# CORE_PRM register map
Vendor: Texas Instruments
Peripheral module from a debugger description file (folder TDA2Px).
Registers are 32-bit, access per field, reset 0x2 unless marked. A register's access mark holds for its fields unless they carry their own. Offsets are as the file gives them; lines under a group give offsets from that group; [hi:lo] are bit positions; {n}, {i} and the like mark numbered series; 'fields as' and 'values as' point back to an identical list; <NAME> marks a mode.

## CORE_PRM
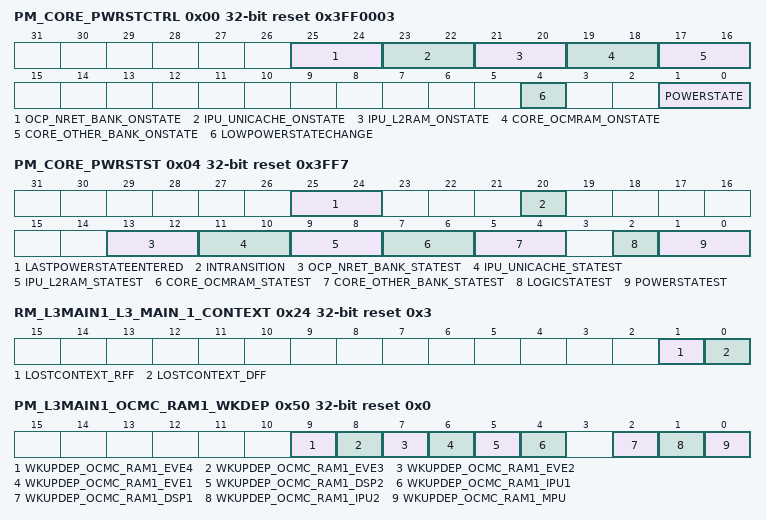
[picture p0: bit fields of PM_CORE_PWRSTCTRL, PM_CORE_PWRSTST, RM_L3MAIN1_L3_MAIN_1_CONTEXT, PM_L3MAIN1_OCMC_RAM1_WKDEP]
0x00 PM_CORE_PWRSTCTRL reset 0x3FF0003 — This register controls the CORE power state to reach upon a domain sleep transition
  [25:24] OCP_NRET_BANK_ONSTATE ro — OCP_WP bank and DMM bank2 state when domain is ON.
    3=MEM_ON (Memory bank is on when the domain is ON.)
  [23:22] IPU_UNICACHE_ONSTATE ro — IPU UNICACHE bank state when domain is ON.
    3=MEM_ON (Memory bank is on when the domain is ON.)
  [21:20] IPU_L2RAM_ONSTATE ro — IPU L2 bank state when domain is ON.
    3=MEM_ON (Memory bank is on when the domain is ON.)
  [19:18] CORE_OCMRAM_ONSTATE ro — OCMRAM bank state when domain is ON.
    3=MEM_ON (Memory bank is on when the domain is ON.)
  [17:16] CORE_OTHER_BANK_ONSTATE ro — DMA/ICR bank and DMM bank1 state when domain is ON.
    3=MEM_ON (Memory bank is on when the domain is ON.)
  [4] LOWPOWERSTATECHANGE rw — Power state change request when domain has already performed a sleep transition. Allows going into deeper low power state without waking up the power domain.
    0=DIS (Do not request a low power state change.); 1=EN (Request a low power state change. This bit is automatically cleared when the power state is effectively changed or when power state is ON.)
  [1:0] POWERSTATE rw — Power state control
    1=RET (Reserved); 2=INACT (Reserved); 3=ON (ON State)
0x04 PM_CORE_PWRSTST reset 0x3FF7 — This register provides a status on the current CORE power domain state. [warm reset insensitive]
  [25:24] LASTPOWERSTATEENTERED rw — Last low power state entered. Set to 0x3 upon write of the same only. This register is intended for debug purpose only.
    0=OFF (Power domain was previously OFF); 1=RET (Reserved); 2=INACTIVE (Reserved); 3=ON (Power domain was previously ON-ACTIVE)
  [20] INTRANSITION ro — Domain transition status
    0=NO (No on-going transition on power domain); 1=ONGOING (Power domain transition is in progress.)
  [13:12] OCP_NRET_BANK_STATEST ro — OCP_WP bank and DMM bank2 state status
    0=MEM_OFF (Memory is OFF); 3=MEM_ON (Memory is ON)
  [11:10] IPU_UNICACHE_STATEST ro — IPU UNICACHE bank state status
    0=MEM_OFF (Memory is OFF); 1=MEM_RET (Reserved); 3=MEM_ON (Memory is ON)
  [9:8] IPU_L2RAM_STATEST ro — IPU L2 bank state status
    values as IPU_UNICACHE_STATEST
  [7:6] CORE_OCMRAM_STATEST ro — OCMRAM bank state status
    values as IPU_UNICACHE_STATEST
  [5:4] CORE_OTHER_BANK_STATEST ro — DMA/ICR bank and DMM bank1 state status
    values as IPU_UNICACHE_STATEST
  [2] LOGICSTATEST ro — Logic state status
    0=OFF (Reserved); 1=ON (Logic in domain is ON)
  [1:0] POWERSTATEST ro — Current power state status
    1=RET (Reserved); 2=INACTIVE (Reserved); 3=ON (Power domain is ON-ACTIVE)
0x24 RM_L3MAIN1_L3_MAIN_1_CONTEXT reset 0x3 — This register contains dedicated L3_MAIN_1 context statuses. [warm reset insensitive]
  [1] LOSTCONTEXT_RFF rw — Specify if RFF-based context has been lost due to a previous power transition or other reset source. (set upon assertion of CORE_PWRON_RET_RST signal)
    0=MAINTAINED (Context has been maintained); 1=LOST (Context has been lost)
  [0] LOSTCONTEXT_DFF rw — Specify if DFF-based context has been lost due to a previous power transition or other reset source. (set upon assertion of CORE_RST signal)
    values as LOSTCONTEXT_RFF
0x2C RM_L3MAIN1_GPMC_CONTEXT — This register contains dedicated GPMC context statuses. [warm reset insensitive]
  [1] LOSTCONTEXT_RFF rw — Specify if RFF-based context has been lost due to a previous power transition or other reset source. (set upon assertion of CORE_RET_RST signal)
    values as RM_L3MAIN1_L3_MAIN_1_CONTEXT.LOSTCONTEXT_RFF
0x34 RM_L3MAIN1_MMU_EDMA_CONTEXT — This register contains dedicated MMU context statuses. [warm reset insensitive]
  [1] LOSTCONTEXT_RFF rw — Specify if RFF-based context has been lost due to a previous power transition or other reset source. (set upon assertion of CORE_PWRON_RET_RST signal)
    values as RM_L3MAIN1_L3_MAIN_1_CONTEXT.LOSTCONTEXT_RFF
0x4C RM_L3MAIN1_MMU_PCIESS_CONTEXT — This register contains dedicated MMU context statuses. [warm reset insensitive]
  fields as RM_L3MAIN1_MMU_EDMA_CONTEXT
0x50 PM_L3MAIN1_OCMC_RAM1_WKDEP reset 0x0 — This register controls wakeup dependency based on OCMC_RAM1 service requests.
  [9] WKUPDEP_OCMC_RAM1_EVE4 rw — Wakeup dependency from OCMC_RAM1 module (SWakeup signal) towards EVE4 + L3_MAIN1 + L4PER1 + L4PER2 + L4PER3 domainsEVE4 is not supported in this family of devices.
    0=DISABLED (Dependency is disabled); 1=ENABLED (Dependency is enabled)
  [8] WKUPDEP_OCMC_RAM1_EVE3 rw — Wakeup dependency from OCMC_RAM1 module (SWakeup signal) towards EVE3 + L3_MAIN1 + L4PER1 + L4PER2 + L4PER3 domainsEVE3 is not supported in this family of devices.
    values as WKUPDEP_OCMC_RAM1_EVE4
  [7] WKUPDEP_OCMC_RAM1_EVE2 rw — Wakeup dependency from OCMC_RAM1 module (SWakeup signal) towards EVE2 + L3_MAIN1 + L4PER1 + L4PER2 + L4PER3 domains
    values as WKUPDEP_OCMC_RAM1_EVE4
  [6] WKUPDEP_OCMC_RAM1_EVE1 rw — Wakeup dependency from OCMC_RAM1 module (SWakeup signal) towards EVE1 + L3_MAIN1 + L4PER1 + L4PER2 + L4PER3 domains
    values as WKUPDEP_OCMC_RAM1_EVE4
  [5] WKUPDEP_OCMC_RAM1_DSP2 rw — Wakeup dependency from OCMC_RAM1 module (SWakeup signal) towards DSP2 + L3_MAIN1 + L4PER1 + L4PER2 + L4PER3 domains
    values as WKUPDEP_OCMC_RAM1_EVE4
  [4] WKUPDEP_OCMC_RAM1_IPU1 rw — Wakeup dependency from OCMC_RAM1 module (SWakeup signal) towards IPU1 + L3_MAIN1 + L4PER1 + L4PER2 + L4PER3 domains
    values as WKUPDEP_OCMC_RAM1_EVE4
  [2] WKUPDEP_OCMC_RAM1_DSP1 rw — Wakeup dependency from OCMC_RAM1 module (SWakeup signal) towards DSP + L3_MAIN1 + L4PER1 + L4PER2 + L4PER3 domains
    values as WKUPDEP_OCMC_RAM1_EVE4
  [1] WKUPDEP_OCMC_RAM1_IPU2 rw — Wakeup dependency from OCMC_RAM1 module (SWakeup signal) towards IPU2 + L3_MAIN1 + L4PER1 + L4PER2 + L4PER3 domains
    0=Dependency_is_disabled; 1=Dependency_is_enabled
  [0] WKUPDEP_OCMC_RAM1_MPU rw — Wakeup dependency from OCMC_RAM1 module (SWakeup signal) towards MPU + L3_MAIN1 + L4PER1 + L4PER2 + L4PER3 domains
    values as WKUPDEP_OCMC_RAM1_EVE4
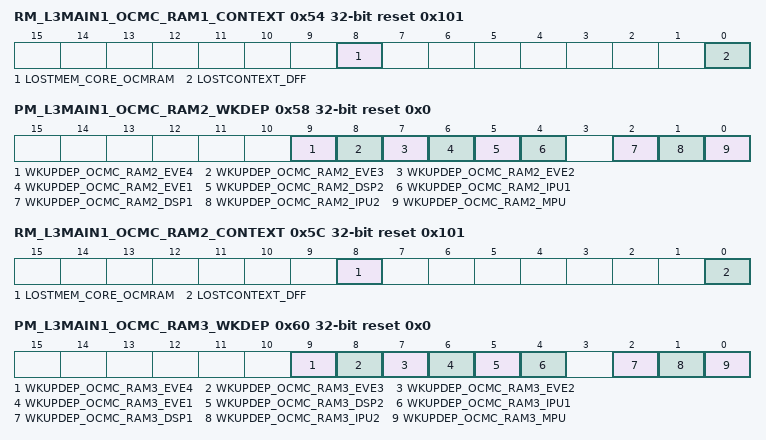
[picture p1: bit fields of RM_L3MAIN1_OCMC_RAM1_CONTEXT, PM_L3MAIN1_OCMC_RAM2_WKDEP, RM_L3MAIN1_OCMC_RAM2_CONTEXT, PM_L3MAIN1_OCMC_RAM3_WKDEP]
0x54 RM_L3MAIN1_OCMC_RAM1_CONTEXT reset 0x101 — This register contains dedicated OCMC_RAM context statuses. [warm reset insensitive]
  [8] LOSTMEM_CORE_OCMRAM rw — Specify if memory-based context in CORE_OCMRAM memory bank has been lost due to a previous power transition or other reset source (not affected by a global warm reset).
    values as RM_L3MAIN1_L3_MAIN_1_CONTEXT.LOSTCONTEXT_RFF
  [0] LOSTCONTEXT_DFF rw — Specify if DFF-based context has been lost due to a previous power transition or other reset source. (set upon assertion of CORE_RST signal)
    values as RM_L3MAIN1_L3_MAIN_1_CONTEXT.LOSTCONTEXT_RFF
0x58 PM_L3MAIN1_OCMC_RAM2_WKDEP reset 0x0 — This register controls wakeup dependency based on OCMC_RAM2 service requests.
  [9] WKUPDEP_OCMC_RAM2_EVE4 rw — Wakeup dependency from OCMC_RAM2 module (SWakeup signal) towards EVE4 + L3_MAIN1 + L4PER1 + L4PER2 + L4PER3 domainsEVE4 is not supported in this family of devices.
    values as PM_L3MAIN1_OCMC_RAM1_WKDEP.WKUPDEP_OCMC_RAM1_EVE4
  [8] WKUPDEP_OCMC_RAM2_EVE3 rw — Wakeup dependency from OCMC_RAM2 module (SWakeup signal) towards EVE3 + L3_MAIN1 + L4PER1 + L4PER2 + L4PER3 domainsEVE3 is not supported in this family of devices.
    values as PM_L3MAIN1_OCMC_RAM1_WKDEP.WKUPDEP_OCMC_RAM1_EVE4
  [7] WKUPDEP_OCMC_RAM2_EVE2 rw — Wakeup dependency from OCMC_RAM2 module (SWakeup signal) towards EVE2 + L3_MAIN1 + L4PER1 + L4PER2 + L4PER3 domains
    values as PM_L3MAIN1_OCMC_RAM1_WKDEP.WKUPDEP_OCMC_RAM1_EVE4
  [6] WKUPDEP_OCMC_RAM2_EVE1 rw — Wakeup dependency from OCMC_RAM2 module (SWakeup signal) towards EVE1 + L3_MAIN1 + L4PER1 + L4PER2 + L4PER3 domains
    values as PM_L3MAIN1_OCMC_RAM1_WKDEP.WKUPDEP_OCMC_RAM1_EVE4
  [5] WKUPDEP_OCMC_RAM2_DSP2 rw — Wakeup dependency from OCMC_RAM2 module (SWakeup signal) towards DSP2 + L3_MAIN1 + L4PER1 + L4PER2 + L4PER3 domains
    values as PM_L3MAIN1_OCMC_RAM1_WKDEP.WKUPDEP_OCMC_RAM1_EVE4
  [4] WKUPDEP_OCMC_RAM2_IPU1 rw — Wakeup dependency from OCMC_RAM2 module (SWakeup signal) towards IPU1 + L3_MAIN1 + L4PER1 + L4PER2 + L4PER3 domains
    values as PM_L3MAIN1_OCMC_RAM1_WKDEP.WKUPDEP_OCMC_RAM1_EVE4
  [2] WKUPDEP_OCMC_RAM2_DSP1 rw — Wakeup dependency from OCMC_RAM2 module (SWakeup signal) towards DSP + L3_MAIN1 + L4PER1 + L4PER2 + L4PER3 domains
    values as PM_L3MAIN1_OCMC_RAM1_WKDEP.WKUPDEP_OCMC_RAM1_EVE4
  [1] WKUPDEP_OCMC_RAM2_IPU2 rw — Wakeup dependency from OCMC_RAM2 module (SWakeup signal) towards IPU2 + L3_MAIN1 + L4PER1 + L4PER2 + L4PER3 domains
    0=Dependency_is_disabled; 1=Dependency_is_enabled
  [0] WKUPDEP_OCMC_RAM2_MPU rw — Wakeup dependency from OCMC_RAM2 module (SWakeup signal) towards MPU + L3_MAIN1 + L4PER1 + L4PER2 + L4PER3 domains
    values as PM_L3MAIN1_OCMC_RAM1_WKDEP.WKUPDEP_OCMC_RAM1_EVE4
0x5C RM_L3MAIN1_OCMC_RAM2_CONTEXT reset 0x101 — This register contains dedicated OCMC_RAM2 context statuses. [warm reset insensitive]
  fields as RM_L3MAIN1_OCMC_RAM1_CONTEXT
0x60 PM_L3MAIN1_OCMC_RAM3_WKDEP reset 0x0 — This register controls wakeup dependency based on OCMC_RAM3 service requests.
  [9] WKUPDEP_OCMC_RAM3_EVE4 rw — Wakeup dependency from OCMC_RAM3 module (SWakeup signal) towards EVE4 + L3_MAIN1 + L4PER1 + L4PER2 + L4PER3 domainsEVE4 is not supported in this family of devices.
    values as PM_L3MAIN1_OCMC_RAM1_WKDEP.WKUPDEP_OCMC_RAM1_EVE4
  [8] WKUPDEP_OCMC_RAM3_EVE3 rw — Wakeup dependency from OCMC_RAM3 module (SWakeup signal) towards EVE3 + L3_MAIN1 + L4PER1 + L4PER2 + L4PER3 domainsEVE3 is not supported in this family of devices.
    values as PM_L3MAIN1_OCMC_RAM1_WKDEP.WKUPDEP_OCMC_RAM1_EVE4
  [7] WKUPDEP_OCMC_RAM3_EVE2 rw — Wakeup dependency from OCMC_RAM3 module (SWakeup signal) towards EVE2 + L3_MAIN1 + L4PER1 + L4PER2 + L4PER3 domains
    values as PM_L3MAIN1_OCMC_RAM1_WKDEP.WKUPDEP_OCMC_RAM1_EVE4
  [6] WKUPDEP_OCMC_RAM3_EVE1 rw — Wakeup dependency from OCMC_RAM3 module (SWakeup signal) towards EVE1 + L3_MAIN1 + L4PER1 + L4PER2 + L4PER3 domains
    values as PM_L3MAIN1_OCMC_RAM1_WKDEP.WKUPDEP_OCMC_RAM1_EVE4
  [5] WKUPDEP_OCMC_RAM3_DSP2 rw — Wakeup dependency from OCMC_RAM3 module (SWakeup signal) towards DSP2 + L3_MAIN1 + L4PER1 + L4PER2 + L4PER3 domains
    values as PM_L3MAIN1_OCMC_RAM1_WKDEP.WKUPDEP_OCMC_RAM1_EVE4
  [4] WKUPDEP_OCMC_RAM3_IPU1 rw — Wakeup dependency from OCMC_RAM3 module (SWakeup signal) towards IPU1 + L3_MAIN1 + L4PER1 + L4PER2 + L4PER3 domains
    values as PM_L3MAIN1_OCMC_RAM1_WKDEP.WKUPDEP_OCMC_RAM1_EVE4
  [2] WKUPDEP_OCMC_RAM3_DSP1 rw — Wakeup dependency from OCMC_RAM3 module (SWakeup signal) towards DSP + L3_MAIN1 + L4PER1 + L4PER2 + L4PER3 domains
    values as PM_L3MAIN1_OCMC_RAM1_WKDEP.WKUPDEP_OCMC_RAM1_EVE4
  [1] WKUPDEP_OCMC_RAM3_IPU2 rw — Wakeup dependency from OCMC_RAM3 module RW 0x0 (SWakeup signal) towards IPU2 + L3_MAIN1 + L4PER1 + L4PER2 + L4PER3 domains
    0=Dependency_is_disabled; 1=Dependency_is_enabled
  [0] WKUPDEP_OCMC_RAM3_MPU rw — Wakeup dependency from OCMC_RAM3 module (SWakeup signal) towards MPU + L3_MAIN1 + L4PER1 + L4PER2 + L4PER3 domains
    values as PM_L3MAIN1_OCMC_RAM1_WKDEP.WKUPDEP_OCMC_RAM1_EVE4
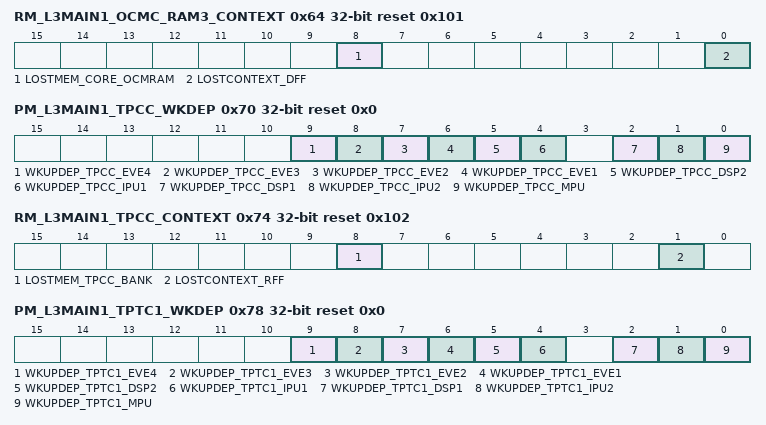
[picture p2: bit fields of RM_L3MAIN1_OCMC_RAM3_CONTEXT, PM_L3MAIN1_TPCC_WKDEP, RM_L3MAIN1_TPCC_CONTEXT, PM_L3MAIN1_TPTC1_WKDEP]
0x64 RM_L3MAIN1_OCMC_RAM3_CONTEXT reset 0x101 — This register contains dedicated OCMC_RAM3 context statuses. [warm reset insensitive]
  fields as RM_L3MAIN1_OCMC_RAM1_CONTEXT
0x70 PM_L3MAIN1_TPCC_WKDEP reset 0x0 — This register controls wakeup dependency based on TPCC service requests.
  [9] WKUPDEP_TPCC_EVE4 rw — Wakeup dependency from TPCC module (SWakeup signal) towards EVE4 + L3_MAIN1 + L4PER1 + L4PER2 + L4PER3 domainsEVE4 is not supported in this family of devices.
    values as PM_L3MAIN1_OCMC_RAM1_WKDEP.WKUPDEP_OCMC_RAM1_EVE4
  [8] WKUPDEP_TPCC_EVE3 rw — Wakeup dependency from TPCC module (SWakeup signal) towards EVE3 + L3_MAIN1 + L4PER1 + L4PER2 + L4PER3 domainsEVE3 is not supported in this family of devices.
    values as PM_L3MAIN1_OCMC_RAM1_WKDEP.WKUPDEP_OCMC_RAM1_EVE4
  [7] WKUPDEP_TPCC_EVE2 rw — Wakeup dependency from TPCC module (SWakeup signal) towards EVE2 + L3_MAIN1 + L4PER1 + L4PER2 + L4PER3 domains
    values as PM_L3MAIN1_OCMC_RAM1_WKDEP.WKUPDEP_OCMC_RAM1_EVE4
  [6] WKUPDEP_TPCC_EVE1 rw — Wakeup dependency from TPCC module (SWakeup signal) towards EVE1 + L3_MAIN1 + L4PER1 + L4PER2 + L4PER3 domains
    values as PM_L3MAIN1_OCMC_RAM1_WKDEP.WKUPDEP_OCMC_RAM1_EVE4
  [5] WKUPDEP_TPCC_DSP2 rw — Wakeup dependency from TPCC module (SWakeup signal) towards DSP2 + L3_MAIN1 + L4PER1 + L4PER2 + L4PER3 domains
    values as PM_L3MAIN1_OCMC_RAM1_WKDEP.WKUPDEP_OCMC_RAM1_EVE4
  [4] WKUPDEP_TPCC_IPU1 rw — Wakeup dependency from TPCC module (SWakeup signal) towards IPU1 + L3_MAIN1 + L4PER1 + L4PER2 + L4PER3 domains
    values as PM_L3MAIN1_OCMC_RAM1_WKDEP.WKUPDEP_OCMC_RAM1_EVE4
  [2] WKUPDEP_TPCC_DSP1 rw — Wakeup dependency from TPCC module (SWakeup signal) towards DSP + L3_MAIN1 + L4PER1 + L4PER2 + L4PER3 domains
    values as PM_L3MAIN1_OCMC_RAM1_WKDEP.WKUPDEP_OCMC_RAM1_EVE4
  [1] WKUPDEP_TPCC_IPU2 rw — Wakeup dependency from TPCC module (SWakeup signal) towards IPU2 + L3_MAIN1 + L4PER1 + L4PER2 + L4PER3 domains
    0=Dependency_is_disabled; 1=Dependency_is_enabled
  [0] WKUPDEP_TPCC_MPU rw — Wakeup dependency from TPCC module (SWakeup signal) towards MPU + L3_MAIN1 + L4PER1 + L4PER2 + L4PER3 domains
    values as PM_L3MAIN1_OCMC_RAM1_WKDEP.WKUPDEP_OCMC_RAM1_EVE4
0x74 RM_L3MAIN1_TPCC_CONTEXT reset 0x102 — This register contains dedicated TPCC context statuses. [warm reset insensitive]
  [8] LOSTMEM_TPCC_BANK rw — Specify if memory-based context in TPCC_MEM memory bank has been lost due to a previous power transition or other reset source (not affected by a global warm reset).
    values as RM_L3MAIN1_L3_MAIN_1_CONTEXT.LOSTCONTEXT_RFF
  [1] LOSTCONTEXT_RFF rw — Specify if RFF-based context has been lost due to a previous power transition or other reset source. (set upon assertion of CORE_RET_RST signal)
    values as RM_L3MAIN1_L3_MAIN_1_CONTEXT.LOSTCONTEXT_RFF
0x78 PM_L3MAIN1_TPTC1_WKDEP reset 0x0 — This register controls wakeup dependency based on TPTC service requests.
  [9] WKUPDEP_TPTC1_EVE4 rw — Wakeup dependency from TPTC module (SWakeup signal) towards EVE4 + L3_MAIN1 + L4PER1 + L4PER2 + L4PER3 domainsEVE4 is not supported in this family of devices.
    values as PM_L3MAIN1_OCMC_RAM1_WKDEP.WKUPDEP_OCMC_RAM1_EVE4
  [8] WKUPDEP_TPTC1_EVE3 rw — Wakeup dependency from TPTC module (SWakeup signal) towards EVE3 + L3_MAIN1 + L4PER1 + L4PER2 + L4PER3 domainsEVE3 is not supported in this family of devices.
    values as PM_L3MAIN1_OCMC_RAM1_WKDEP.WKUPDEP_OCMC_RAM1_EVE4
  [7] WKUPDEP_TPTC1_EVE2 rw — Wakeup dependency from TPTC module (SWakeup signal) towards EVE2 + L3_MAIN1 + L4PER1 + L4PER2 + L4PER3 domains
    values as PM_L3MAIN1_OCMC_RAM1_WKDEP.WKUPDEP_OCMC_RAM1_EVE4
  [6] WKUPDEP_TPTC1_EVE1 rw — Wakeup dependency from TPTC module (SWakeup signal) towards EVE1 + L3_MAIN1 + L4PER1 + L4PER2 + L4PER3 domains
    values as PM_L3MAIN1_OCMC_RAM1_WKDEP.WKUPDEP_OCMC_RAM1_EVE4
  [5] WKUPDEP_TPTC1_DSP2 rw — Wakeup dependency from TPTC module (SWakeup signal) towards DSP2 + L3_MAIN1 + L4PER1 + L4PER2 + L4PER3 domains
    values as PM_L3MAIN1_OCMC_RAM1_WKDEP.WKUPDEP_OCMC_RAM1_EVE4
  [4] WKUPDEP_TPTC1_IPU1 rw — Wakeup dependency from TPTC module (SWakeup signal) towards IPU1 + L3_MAIN1 + L4PER1 + L4PER2 + L4PER3 domains
    values as PM_L3MAIN1_OCMC_RAM1_WKDEP.WKUPDEP_OCMC_RAM1_EVE4
  [2] WKUPDEP_TPTC1_DSP1 rw — Wakeup dependency from TPTC module (SWakeup signal) towards DSP + L3_MAIN1 + L4PER1 + L4PER2 + L4PER3 domains
    values as PM_L3MAIN1_OCMC_RAM1_WKDEP.WKUPDEP_OCMC_RAM1_EVE4
  [1] WKUPDEP_TPTC1_IPU2 rw — Wakeup dependency from TPTC module (SWakeup signal) towards IPU2 + L3_MAIN1 + L4PER1 + L4PER2 + L4PER3 domains
    0=Dependency_is_disabled; 1=Dependency_is_enabled
  [0] WKUPDEP_TPTC1_MPU rw — Wakeup dependency from TPTC module (SWakeup signal) towards MPU + L3_MAIN1 + L4PER1 + L4PER2 + L4PER3 domains
    values as PM_L3MAIN1_OCMC_RAM1_WKDEP.WKUPDEP_OCMC_RAM1_EVE4
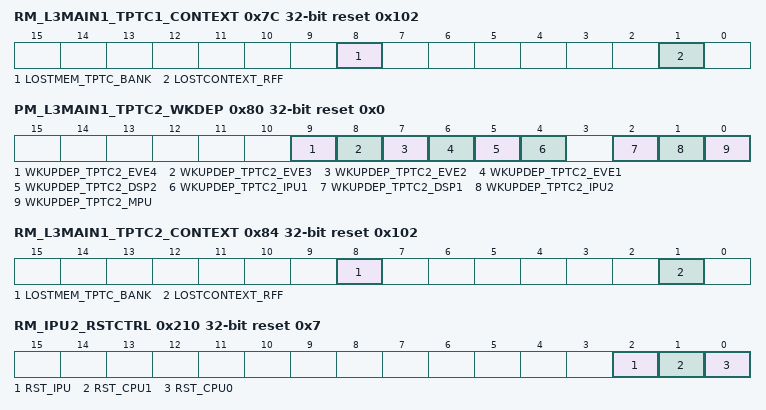
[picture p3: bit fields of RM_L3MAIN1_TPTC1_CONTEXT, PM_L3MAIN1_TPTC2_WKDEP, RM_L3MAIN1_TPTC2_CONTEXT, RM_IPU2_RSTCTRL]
0x7C RM_L3MAIN1_TPTC1_CONTEXT reset 0x102 — This register contains dedicated TPTC1 context statuses. [warm reset insensitive]
  [8] LOSTMEM_TPTC_BANK rw — Specify if memory-based context in TPTC_MEM memory bank has been lost due to a previous power transition or other reset source (not affected by a global warm reset).
    values as RM_L3MAIN1_L3_MAIN_1_CONTEXT.LOSTCONTEXT_RFF
  [1] LOSTCONTEXT_RFF rw — Specify if RFF-based context has been lost due to a previous power transition or other reset source. (set upon assertion of CORE_RET_RST signal)
    values as RM_L3MAIN1_L3_MAIN_1_CONTEXT.LOSTCONTEXT_RFF
0x80 PM_L3MAIN1_TPTC2_WKDEP reset 0x0 — This register controls wakeup dependency based on TPTC service requests.
  [9] WKUPDEP_TPTC2_EVE4 rw — Wakeup dependency from TPTC module (SWakeup signal) towards EVE4 + L3_MAIN1 + L4PER1 + L4PER2 + L4PER3 domainsEVE4 is not supported in this family of devices.
    values as PM_L3MAIN1_OCMC_RAM1_WKDEP.WKUPDEP_OCMC_RAM1_EVE4
  [8] WKUPDEP_TPTC2_EVE3 rw — Wakeup dependency from TPTC module (SWakeup signal) towards EVE3 + L3_MAIN1 + L4PER1 + L4PER2 + L4PER3 domainsEVE3 is not supported in this family of devices.
    values as PM_L3MAIN1_OCMC_RAM1_WKDEP.WKUPDEP_OCMC_RAM1_EVE4
  [7] WKUPDEP_TPTC2_EVE2 rw — Wakeup dependency from TPTC module (SWakeup signal) towards EVE2 + L3_MAIN1 + L4PER1 + L4PER2 + L4PER3 domains
    values as PM_L3MAIN1_OCMC_RAM1_WKDEP.WKUPDEP_OCMC_RAM1_EVE4
  [6] WKUPDEP_TPTC2_EVE1 rw — Wakeup dependency from TPTC module (SWakeup signal) towards EVE1 + L3_MAIN1 + L4PER1 + L4PER2 + L4PER3 domains
    values as PM_L3MAIN1_OCMC_RAM1_WKDEP.WKUPDEP_OCMC_RAM1_EVE4
  [5] WKUPDEP_TPTC2_DSP2 rw — Wakeup dependency from TPTC module (SWakeup signal) towards DSP2 + L3_MAIN1 + L4PER1 + L4PER2 + L4PER3 domains
    values as PM_L3MAIN1_OCMC_RAM1_WKDEP.WKUPDEP_OCMC_RAM1_EVE4
  [4] WKUPDEP_TPTC2_IPU1 rw — Wakeup dependency from TPTC module (SWakeup signal) towards IPU1 + L3_MAIN1 + L4PER1 + L4PER2 + L4PER3 domains
    values as PM_L3MAIN1_OCMC_RAM1_WKDEP.WKUPDEP_OCMC_RAM1_EVE4
  [2] WKUPDEP_TPTC2_DSP1 rw — Wakeup dependency from TPTC module (SWakeup signal) towards DSP + L3_MAIN1 + L4PER1 + L4PER2 + L4PER3 domains
    values as PM_L3MAIN1_OCMC_RAM1_WKDEP.WKUPDEP_OCMC_RAM1_EVE4
  [1] WKUPDEP_TPTC2_IPU2 rw — Wakeup dependency from TPTC module (SWakeup signal) towards IPU2 + L3_MAIN1 + L4PER1 + L4PER2 + L4PER3 domains
    0=Dependency_is_disabled; 1=Dependency_is_enabled
  [0] WKUPDEP_TPTC2_MPU rw — Wakeup dependency from TPTC module (SWakeup signal) towards MPU + L3_MAIN1 + L4PER1 + L4PER2 + L4PER3 domains
    values as PM_L3MAIN1_OCMC_RAM1_WKDEP.WKUPDEP_OCMC_RAM1_EVE4
0x84 RM_L3MAIN1_TPTC2_CONTEXT reset 0x102 — This register contains dedicated TPTC2 context statuses. [warm reset insensitive]
  fields as RM_L3MAIN1_TPTC1_CONTEXT
0x210 RM_IPU2_RSTCTRL reset 0x7 — This register controls the release of the IPU2 sub-system resets.
  [2] RST_IPU rw — IPU system reset control.
    0=CLEAR (Reset is cleared for IPU CACHE MMU); 1=ASSERT (Reset is asserted for the IPU CACHE MMU)
  [1] RST_CPU1 rw — IPU Cortex M4 CPU1 reset control
    0=CLEAR (Reset is cleared for the IPU Cortex M4 CPU1); 1=ASSERT (Reset is asserted for the IPU Cortex M4 CPU1)
  [0] RST_CPU0 rw — IPU Cortex M4 CPU0 reset control.
    0=CLEAR (Reset is cleared for the IPU Cortex M4 CPU0); 1=ASSERT (Reset is asserted for the IPU Cortex M4 CPU0)
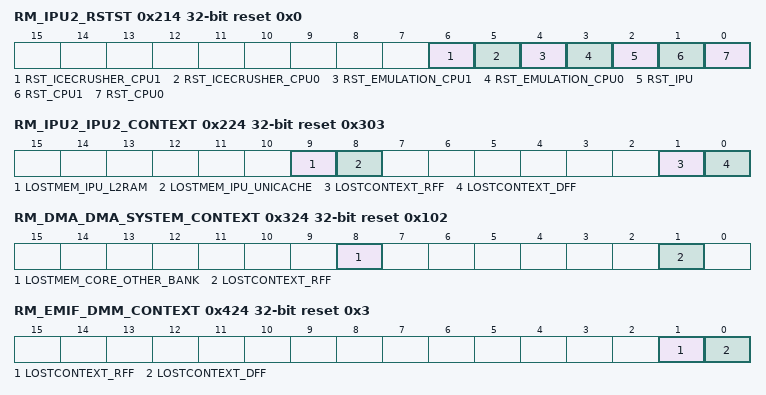
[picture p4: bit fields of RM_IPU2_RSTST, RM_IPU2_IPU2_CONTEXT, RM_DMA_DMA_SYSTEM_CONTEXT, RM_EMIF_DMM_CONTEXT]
0x214 RM_IPU2_RSTST reset 0x0 — This register logs the different reset sources of the IPU2 SS. Each bit is set upon release of the domain reset signal. Must be cleared by software. [warm reset insensitive]
  [6] RST_ICECRUSHER_CPU1 rw — Cortex M4 CPU1 has been reset due to IPU ICECRUSHER1 reset source
    0=RESET_NO (No icecrusher reset); 1=RESET_YES (CPU1 has been reset upon icecrusher reset)
  [5] RST_ICECRUSHER_CPU0 rw — Cortex M4 CPU0 has been reset due to IPU ICECRUSHER0 reset source
    0=RESET_NO (No icecrusher reset); 1=RESET_YES (CPU0 has been reset upon icecrusher reset)
  [4] RST_EMULATION_CPU1 rw — Cortex M4 CPU1 has been reset due to emulation reset source e.g. assert reset command initiated by the icepick module
    0=RESET_NO (No emulation reset); 1=RESET_YES (CPU1 has been reset upon emulation reset)
  [3] RST_EMULATION_CPU0 rw — Cortex M4 CPU0 has been reset due to emulation reset source e.g. assert reset command initiated by the icepick module
    0=RESET_NO (No emulation reset); 1=RESET_YES (CPU0 has been reset upon emulation reset)
  [2] RST_IPU rw — IPU system SW reset status
    0=RESET_NO (No SW reset occurred); 1=RESET_YES (IPU MMU and CACHE interface has been reset upon SW reset)
  [1] RST_CPU1 rw — IPU Cortex-M4 CPU1 SW reset status
    0=RESET_NO (No SW reset occurred); 1=RESET_YES (Cortex M4 CPU1 has been reset upon SW reset)
  [0] RST_CPU0 rw — IPU Cortex-M4 CPU0 SW reset status
    0=RESET_NO (No SW reset occurred); 1=RESET_YES (Cortex M4 CPU0 has been reset upon SW reset)
0x224 RM_IPU2_IPU2_CONTEXT reset 0x303 — This register contains dedicated IPU2 context statuses. [warm reset insensitive]
  [all] fields
    values as RM_L3MAIN1_L3_MAIN_1_CONTEXT.LOSTCONTEXT_RFF
  [9] LOSTMEM_IPU_L2RAM rw — Specify if memory-based context in IPU_L2RAM memory bank has been lost due to a previous power transition or other reset source.
  [8] LOSTMEM_IPU_UNICACHE rw — Specify if memory-based context in IPU_UNICACHE memory bank has been lost due to a previous power transition or other reset source.
  [1] LOSTCONTEXT_RFF rw — Specify if RFF-based context has been lost due to a previous power transition or other reset source. (set upon assertion of IPU_RET_RST signal)
  [0] LOSTCONTEXT_DFF rw — Specify if DFF-based context has been lost due to a previous power transition or other reset source. (set upon assertion of IPU_RST signal)
0x324 RM_DMA_DMA_SYSTEM_CONTEXT reset 0x102 — This register contains dedicated SDMA context statuses. [warm reset insensitive]
  [8] LOSTMEM_CORE_OTHER_BANK rw — Specify if memory-based context in CORE_OTHER_BANK memory bank has been lost due to a previous power transition or other reset source.
    values as RM_L3MAIN1_L3_MAIN_1_CONTEXT.LOSTCONTEXT_RFF
  [1] LOSTCONTEXT_RFF rw — Specify if RFF-based context has been lost due to a previous power transition or other reset source. (set upon assertion of DMA_RET_RST signal)
    values as RM_L3MAIN1_L3_MAIN_1_CONTEXT.LOSTCONTEXT_RFF
0x424 RM_EMIF_DMM_CONTEXT reset 0x3 — This register contains dedicated DMM context statuses. [warm reset insensitive]
  [1] LOSTCONTEXT_RFF rw — Specify if RFF-based context has been lost due to a previous power transition or other reset source. (set upon assertion of CORE_PWRON_RET_RST signal)
    values as RM_L3MAIN1_L3_MAIN_1_CONTEXT.LOSTCONTEXT_RFF
  [0] LOSTCONTEXT_DFF rw — Specify if DFF-based context has been lost due to a previous power transition or other reset source. (set upon assertion of CORE_PWRON_RST signal)
    values as RM_L3MAIN1_L3_MAIN_1_CONTEXT.LOSTCONTEXT_RFF
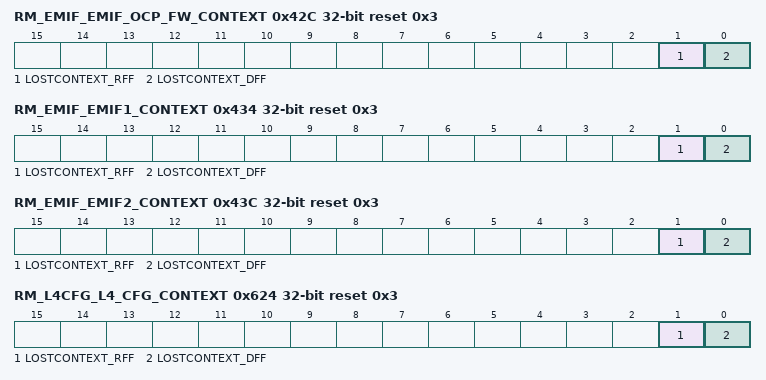
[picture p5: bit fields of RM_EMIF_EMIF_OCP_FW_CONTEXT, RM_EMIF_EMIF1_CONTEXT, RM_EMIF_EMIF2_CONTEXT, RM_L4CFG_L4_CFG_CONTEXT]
0x42C RM_EMIF_EMIF_OCP_FW_CONTEXT reset 0x3 — This register contains dedicated EMIF_OCP_FW context statuses. [warm reset insensitive]
  fields as RM_L3MAIN1_L3_MAIN_1_CONTEXT
0x434 RM_EMIF_EMIF1_CONTEXT reset 0x3 — This register contains dedicated EMIF_1 context statuses. [warm reset insensitive]
  fields as RM_EMIF_DMM_CONTEXT
0x43C RM_EMIF_EMIF2_CONTEXT reset 0x3 — This register contains dedicated EMIF_2 context statuses. [warm reset insensitive]
  fields as RM_EMIF_DMM_CONTEXT
0x444 RM_EMIF_EMIF_DLL_CONTEXT reset 0x1 — This register contains dedicated DLL context statuses. [warm reset insensitive]
  [0] LOSTCONTEXT_DFF rw — Specify if DFF-based context has been lost due to a previous power transition or other reset source. (set upon assertion of DLL_RST signal)
    values as RM_L3MAIN1_L3_MAIN_1_CONTEXT.LOSTCONTEXT_RFF
0x624 RM_L4CFG_L4_CFG_CONTEXT reset 0x3 — This register contains dedicated L4_CFG context statuses. [warm reset insensitive]
  fields as RM_L3MAIN1_L3_MAIN_1_CONTEXT
0x62C RM_L4CFG_SPINLOCK_CONTEXT — This register contains dedicated HW_SEM context statuses. [warm reset insensitive]
  fields as RM_L3MAIN1_GPMC_CONTEXT
0x634 RM_L4CFG_MAILBOX1_CONTEXT — This register contains dedicated MAILBOX1 context statuses. [warm reset insensitive]
  fields as RM_L3MAIN1_GPMC_CONTEXT
0x63C RM_L4CFG_SAR_ROM_CONTEXT reset 0x1 — This register contains dedicated SAR_ROM context statuses. [warm reset insensitive] NOTE: This register is NOT supported on this device.
  [0] LOSTCONTEXT_DFF rw — Specify if DFF-based context has been lost due to a previous power transition or other reset source. (set upon assertion of CORE_RST signal)
    values as RM_L3MAIN1_L3_MAIN_1_CONTEXT.LOSTCONTEXT_RFF
0x644 RM_L4CFG_OCP2SCP2_CONTEXT reset 0x1 — This register contains dedicated OCP2SCP2 context statuses. [warm reset insensitive]
  fields as RM_L4CFG_SAR_ROM_CONTEXT
{0x63C+8i} RM_L4CFG_MAILBOX{i}_CONTEXT (i=2..13) — This register contains dedicated MAILBOX{i} context statuses. [warm reset insensitive]
  fields as RM_L3MAIN1_GPMC_CONTEXT
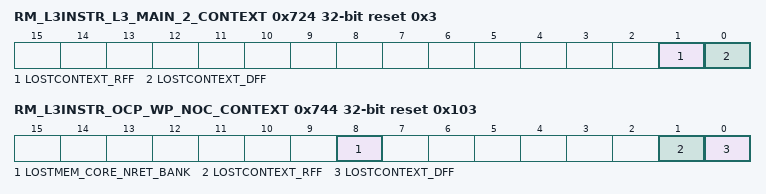
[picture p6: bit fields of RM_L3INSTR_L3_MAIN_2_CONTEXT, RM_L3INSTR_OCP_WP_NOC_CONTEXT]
0x724 RM_L3INSTR_L3_MAIN_2_CONTEXT reset 0x3 — This register contains dedicated L3_3 context statuses. [warm reset insensitive]
  fields as RM_L3MAIN1_L3_MAIN_1_CONTEXT
0x72C RM_L3INSTR_L3_INSTR_CONTEXT reset 0x1 — This register contains dedicated L3_INSTR context statuses. [warm reset insensitive]
  fields as RM_L4CFG_SAR_ROM_CONTEXT
0x744 RM_L3INSTR_OCP_WP_NOC_CONTEXT reset 0x103 — This register contains dedicated OCP_WP1 context statuses. [warm reset insensitive]
  [all] fields
    values as RM_L3MAIN1_L3_MAIN_1_CONTEXT.LOSTCONTEXT_RFF
  [8] LOSTMEM_CORE_NRET_BANK rw — Specify if memory-based context in CORE_NRET_BANK memory bank has been lost due to a previous power transition or other reset source.
  [1] LOSTCONTEXT_RFF rw — Specify if RFF-based context has been lost due to a previous power transition or other reset source. (set upon assertion of CORE_PWRON_RET_RST signal)
  [0] LOSTCONTEXT_DFF rw — Specify if DFF-based context has been lost due to a previous power transition or other reset source. (set upon assertion of CORE_RST signal)
